# MM32F031xxn register map
File version: 1.92
CPU: CM0 r0p0, little endian, no MPU, no FPU, 2 interrupt priority bits
Registers are 32-bit, read-write, reset 0x0 unless marked. A register's access mark holds for its fields unless they carry their own. Offsets are from the block's base; [hi:lo] are bit positions; {n}, {i} and the like mark numbered series.

## AES — Advanced Encryption Standard
Base 0x40026000
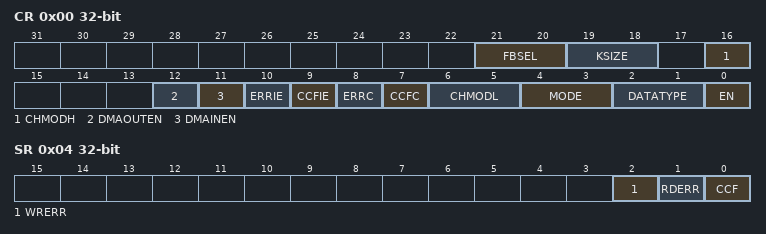
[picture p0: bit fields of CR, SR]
0x00 CR
  [21:20] FBSEL — Feedback selection
  [19:18] KSIZE — Key size
  [16] CHMODH — AES chaining mode high bits
  [12] DMAOUTEN — DMA Enable managing the data output phase
  [11] DMAINEN — DMA Enable managing the data input phase
  [10] ERRIE — Error Interrupt Enable
  [9] CCFIE — Computation Complete Interrupt Enable
  [8] ERRC — Error Clear
  [7] CCFC — Computation Complete Flag Clear
  [6:5] CHMODL — AES chaining mode low bits
  [4:3] MODE — AES mode Of operation
  [2:1] DATATYPE — Data type selection
  [0] EN — AES enable
0x04 SR
  [2] WRERR — Write Error Flag
  [1] RDERR — Read Error Flag
  [0] CCF — Computation Complete Flag
0x08 DINR
  [31:0] DINR — AES Data Input Register
0x0C DOUTR
  [31:0] DOUTR — AES Data Output Register
{0x10+4i} KEYR{i} (i=0..3)
  [31:0] KEYR{i} — AES Key Register {i}
{0x20+4i} IVR{i} (i=0..3)
  [31:0] IVR{i} — AES initialization vector register {i}
{0x20+4i} KEYR{i} (i=4..7)
  [31:0] KEYR{i} — AES Key Register {i}

## BKP — Backup registers
Base 0x4000280C
{0x0+4i} DR{i} (i=1..10) — Backup data register(BKP_DR)
  [15:0] D — Backup data

## COMP — comparator
Base 0x40013C00
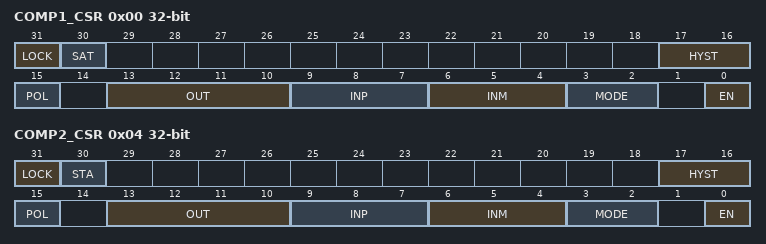
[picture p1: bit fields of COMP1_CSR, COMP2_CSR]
0x00 COMP1_CSR
  [31] LOCK — Comparator 1 lock
  [30] SAT — Comparator 1 output status
  [17:16] HYST — Comparator 1 hysteresis
  [15] POL — Comparator 1 output polarity
  [13:10] OUT — Comparator 1 output selection
  [9:7] INP — Comparator 1 normal phase input selection
  [6:4] INM — Comparator 1 inverting input selection
  [3:2] MODE — Comparator 1 mode
  [0] EN — Comparator 1 enable
0x04 COMP2_CSR
  [31] LOCK — Comparator 2 lock
  [30] STA — Comparator 2 output status
  [17:16] HYST — Comparator 2 hysteresis
  [15] POL — Comparator 2 output polarity
  [13:10] OUT — Comparator 2 output selection
  [9:7] INP — Comparator 2 normal phase input selection
  [6:4] INM — Comparator 2 inverting input selection
  [3:2] MODE — Comparator 2 mode
  [0] EN — Comparator 2 enable

## CRS — CRS registers
Base 0x40006C00
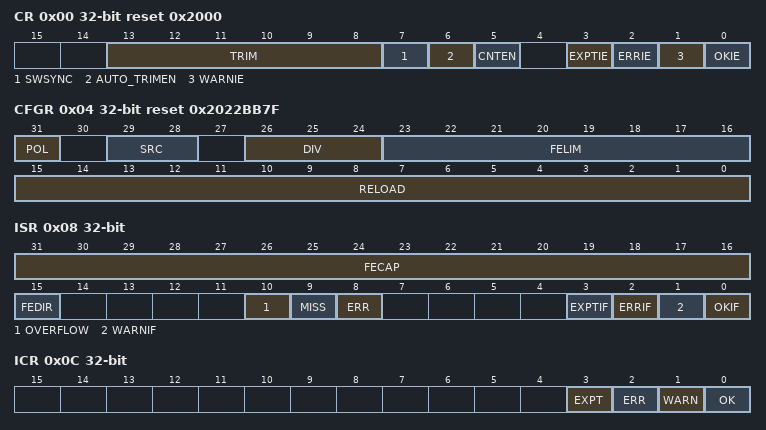
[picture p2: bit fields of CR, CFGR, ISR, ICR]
0x00 CR reset 0x2000 — Control register
  [13:8] TRIM — HSI48 oscillator smooth trimming
  [7] SWSYNC — Generate software SYNC event
  [6] AUTO_TRIMEN — Automatic trimming enable
  [5] CNTEN — Frequency error counter enable
  [3] EXPTIE — Expected SYNC interrupt enable
  [2] ERRIE — Synchronization or trimming error interrupt enable
  [1] WARNIE — SYNC warning interrupt enable
  [0] OKIE — SYNC event OK interrupt enable
0x04 CFGR ro reset 0x2022BB7F — Configuration register
  [31] POL — SYNC polarity selection
  [29:28] SRC — SYNC signal source selection
  [26:24] DIV — SYNC divider
  [23:16] FELIM — Frequency error limit
  [15:0] RELOAD — Counter reload value)
0x08 ISR ro — Interrupt status register
  [31:16] FECAP — Frequency error capture
  [15] FEDIR — Frequency error direction
  [10] OVERFLOW — Trimming overflow or underflow
  [9] MISS — SYNC missed
  [8] ERR — SYNC error)
  [3] EXPTIF — Expected SYNC flag
  [2] ERRIF — Error flag
  [1] WARNIF — SYNC warning flag
  [0] OKIF — SYNC event OK flag
0x0C ICR — Interrupt clear register
  [3] EXPT — Expected SYNC clear flag
  [2] ERR — Error clear flag
  [1] WARN — SYNC warning clear flag
  [0] OK — SYNC event OK clear flag

## DBG — Debug support
Base 0x40013400
0x00 IDCODE ro
  [31:0] DEV_ID — Device identifier
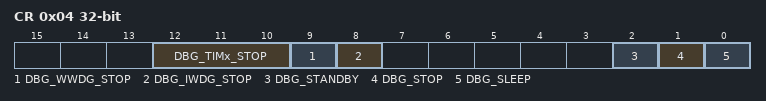
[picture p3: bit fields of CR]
0x04 CR wo
  [12:10] DBG_TIMx_STOP — TIMx counter stopped when core is halted
  [9] DBG_WWDG_STOP — Debug window watchdog when core is halted
  [8] DBG_IWDG_STOP — Debug independent watchdog stopped when core is stopped
  [2] DBG_STANDBY — Debug Standby mode
  [1] DBG_STOP — Debug Stop mode
  [0] DBG_SLEEP — Debug Sleep mode
